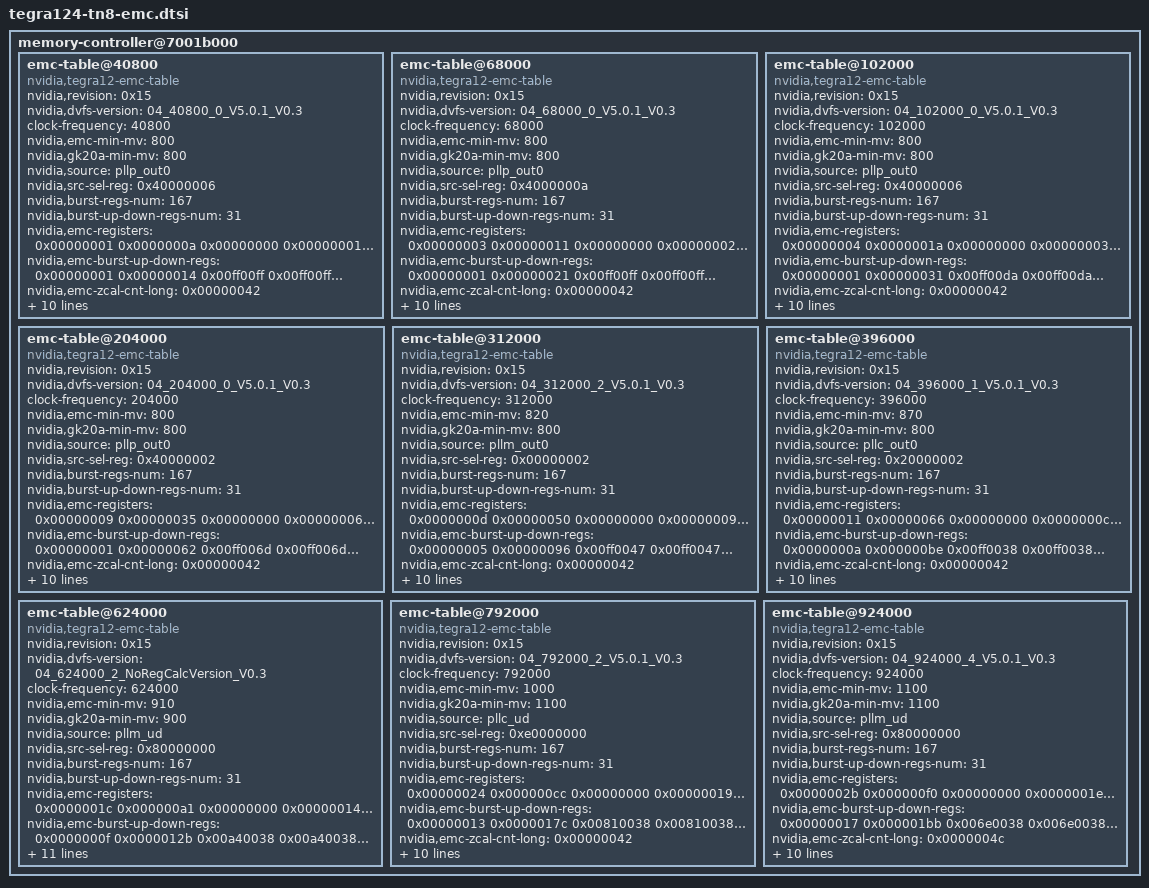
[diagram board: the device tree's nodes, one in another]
memory-controller@7001b000 {
	emc-table@40800 {
		compatible = "nvidia,tegra12-emc-table";
		nvidia,revision = <0x15>;
		nvidia,dvfs-version = "04_40800_0_V5.0.1_V0.3";
		clock-frequency = <40800>;
		nvidia,emc-min-mv = <800>;
		nvidia,gk20a-min-mv = <800>;
		nvidia,source = "pllp_out0";
		nvidia,src-sel-reg = <0x40000006>;
		nvidia,burst-regs-num = <167>;
		nvidia,burst-up-down-regs-num = <31>;
		nvidia,emc-registers = <
			0x00000001
			0x0000000a
			0x00000000
			0x00000001
			0x00000000
			0x00000004
			0x0000000a
			0x00000003
			0x0000000b
			0x00000000
			0x00000000
			0x00000003
			0x00000003
			0x00000000
			0x00000006
			0x00000006
			0x00000006
			0x00000002
			0x00000000
			0x00000005
			0x00000005
			0x00010000
			0x00000004
			0x00000000
			0x00000000
			0x00000000
			0x00000000
			0x00000004
			0x0000000c
			0x0000000d
			0x0000000f
			0x0000012e
			0x00000000
			0x0000004b
			0x00000002
			0x00000002
			0x00000001
			0x00000000
			0x00000008
			0x0000000f
			0x0000000b
			0x0000000b
			0x00000004
			0x00000005
			0x00000004
			0x00000000
			0x00000000
			0x00000005
			0x00000005
			0x00000138
			0x00000000
			0x00000000
			0x00000000
			0x1069aa98
			0x002c00a0
			0x00008000
			0x00064000
			0x00064000
			0x00064000
			0x00064000
			0x00064000
			0x00064000
			0x00064000
			0x00064000
			0x00064000
			0x00064000
			0x00064000
			0x00064000
			0x00064000
			0x00064000
			0x00064000
			0x00064000
			0x00000000
			0x00000000
			0x00000000
			0x00000000
			0x00000000
			0x00000000
			0x00000000
			0x00000000
			0x00000000
			0x00000000
			0x00000000
			0x00000000
			0x00000000
			0x00000000
			0x00000000
			0x00000000
			0x00000000
			0x00000000
			0x00000000
			0x00000000
			0x00000000
			0x00000000
			0x00000000
			0x00000000
			0x00000000
			0x00000000
			0x00000000
			0x00000000
			0x00000000
			0x00000000
			0x00000000
			0x00000000
			0x00000000
			0x00000000
			0x00000000
			0x00000000
			0x00000000
			0x00000000
			0x0007c000
			0x0007c000
			0x0007c000
			0x0007c000
			0x00007c00
			0x00007c00
			0x00007c00
			0x00007c00
			0x100002a0
			0x00000000
			0x00111111
			0x0030a11c
			0x00000000
			0x00000000
			0x77ffc085
			0x00000e0e
			0x81f1f108
			0x07070004
			0x0000003f
			0x016eeeee
			0x51451400
			0x00514514
			0x00514514
			0x51451400
			0x0505003f
			0x00000014
			0x00000000
			0x00000000
			0x00000042
			0x000e000e
			0x000e000e
			0x00000000
			0x00000000
			0xa1430000
			0x00000000
			0x00000004
			0x0000f2f3
			0x80000364
			0x0000000a
			0xb0000001
			0x80000017
			0x00000001
			0x00000001
			0x00000002
			0x00000000
			0x00000002
			0x00000001
			0x00000002
			0x00000008
			0x00000003
			0x00000002
			0x00000003
			0x00000006
			0x06030203
			0x000a0402
			0x74c30303
			0x001f0000>;
		nvidia,emc-burst-up-down-regs = <
			0x00000001
			0x00000014
			0x00ff00ff
			0x00ff00ff
			0x00ff00ff
			0x00ff00ff
			0x00ff00ff
			0x00ff00ff
			0x00ff00ff
			0x00ff0049
			0x00ff0080
			0x00ff0004
			0x00ff0004
			0x000800ff
			0x000000ff
			0x00ff0004
			0x00ff00ff
			0x00ff00ff
			0x00ff0024
			0x00ff00ff
			0x000000ff
			0x000000ff
			0x00ff00ff
			0x000000ff
			0x00ff00ff
			0x00ff00ff
			0x00ff00ff
			0x00ff00ff
			0x00ff00ff
			0x00ff00ff
			0x00ff00ff>;
		nvidia,emc-zcal-cnt-long = <0x00000042>;
		nvidia,emc-acal-interval = <0x001fffff>;
		nvidia,emc-ctt-term_ctrl = <0x00000802>;
		nvidia,emc-cfg = <0x73240000>;
		nvidia,emc-cfg-2 = <0x00000885>;
		nvidia,emc-sel-dpd-ctrl = <0x0004012c>;
		nvidia,emc-cfg-dig-dll = <0x002c0068>;
		nvidia,emc-mode-0 = <0x80001221>;
		nvidia,emc-mode-1 = <0x80100003>;
		nvidia,emc-mode-2 = <0x80200008>;
		nvidia,emc-mode-4 = <0x00000000>;
	};
	emc-table@68000 {
		compatible = "nvidia,tegra12-emc-table";
		nvidia,revision = <0x15>;
		nvidia,dvfs-version = "04_68000_0_V5.0.1_V0.3";
		clock-frequency = <68000>;
		nvidia,emc-min-mv = <800>;
		nvidia,gk20a-min-mv = <800>;
		nvidia,source = "pllp_out0";
		nvidia,src-sel-reg = <0x4000000a>;
		nvidia,burst-regs-num = <167>;
		nvidia,burst-up-down-regs-num = <31>;
		nvidia,emc-registers = <
			0x00000003
			0x00000011
			0x00000000
			0x00000002
			0x00000000
			0x00000004
			0x0000000a
			0x00000003
			0x0000000b
			0x00000000
			0x00000000
			0x00000003
			0x00000003
			0x00000000
			0x00000006
			0x00000006
			0x00000006
			0x00000002
			0x00000000
			0x00000005
			0x00000005
			0x00010000
			0x00000004
			0x00000000
			0x00000000
			0x00000000
			0x00000000
			0x00000004
			0x0000000c
			0x0000000d
			0x0000000f
			0x00000202
			0x00000000
			0x00000080
			0x00000002
			0x00000002
			0x00000001
			0x00000000
			0x0000000f
			0x0000000f
			0x00000013
			0x00000013
			0x00000004
			0x00000005
			0x00000004
			0x00000001
			0x00000000
			0x00000005
			0x00000005
			0x00000213
			0x00000000
			0x00000000
			0x00000000
			0x1069aa98
			0x002c00a0
			0x00008000
			0x00064000
			0x00064000
			0x00064000
			0x00064000
			0x00064000
			0x00064000
			0x00064000
			0x00064000
			0x00064000
			0x00064000
			0x00064000
			0x00064000
			0x00064000
			0x00064000
			0x00064000
			0x00064000
			0x00000000
			0x00000000
			0x00000000
			0x00000000
			0x00000000
			0x00000000
			0x00000000
			0x00000000
			0x00000000
			0x00000000
			0x00000000
			0x00000000
			0x00000000
			0x00000000
			0x00000000
			0x00000000
			0x00000000
			0x00000000
			0x00000000
			0x00000000
			0x00000000
			0x00000000
			0x00000000
			0x00000000
			0x00000000
			0x00000000
			0x00000000
			0x00000000
			0x00000000
			0x00000000
			0x00000000
			0x00000000
			0x00000000
			0x00000000
			0x00000000
			0x00000000
			0x00000000
			0x00000000
			0x0007c000
			0x0007c000
			0x0007c000
			0x0007c000
			0x00007c00
			0x00007c00
			0x00007c00
			0x00007c00
			0x100002a0
			0x00000000
			0x00111111
			0x0030a11c
			0x00000000
			0x00000000
			0x77ffc085
			0x00000e0e
			0x81f1f108
			0x07070004
			0x0000003f
			0x016eeeee
			0x51451400
			0x00514514
			0x00514514
			0x51451400
			0x0505003f
			0x00000022
			0x00000000
			0x00000000
			0x00000042
			0x000e000e
			0x000e000e
			0x00000000
			0x00000000
			0xa1430000
			0x00000000
			0x00000004
			0x0000f2f3
			0x8000050e
			0x0000000a
			0x00000001
			0x8000001e
			0x00000001
			0x00000001
			0x00000002
			0x00000000
			0x00000002
			0x00000001
			0x00000002
			0x00000008
			0x00000003
			0x00000002
			0x00000003
			0x00000006
			0x06030203
			0x000a0402
			0x74230403
			0x001f0000>;
		nvidia,emc-burst-up-down-regs = <
			0x00000001
			0x00000021
			0x00ff00ff
			0x00ff00ff
			0x00ff00b0
			0x00ff00ff
			0x00ff00ec
			0x00ff00ff
			0x00ff00ec
			0x00e90049
			0x00ff0080
			0x00ff0004
			0x00ff0004
			0x000800ff
			0x000000ff
			0x00ff0004
			0x00ff00ff
			0x00ff00a3
			0x00ff0024
			0x00ff00ff
			0x000000ff
			0x000000ef
			0x00ff00ff
			0x000000ef
			0x00ff00ff
			0x00ff00ff
			0x00ee00ef
			0x00ff00ff
			0x00ff00ff
			0x00ff00ff
			0x00ff00ff>;
		nvidia,emc-zcal-cnt-long = <0x00000042>;
		nvidia,emc-acal-interval = <0x001fffff>;
		nvidia,emc-ctt-term_ctrl = <0x00000802>;
		nvidia,emc-cfg = <0x73240000>;
		nvidia,emc-cfg-2 = <0x00000885>;
		nvidia,emc-sel-dpd-ctrl = <0x0004012c>;
		nvidia,emc-cfg-dig-dll = <0x002c0068>;
		nvidia,emc-mode-0 = <0x80001221>;
		nvidia,emc-mode-1 = <0x80100003>;
		nvidia,emc-mode-2 = <0x80200008>;
		nvidia,emc-mode-4 = <0x00000000>;
	};
	emc-table@102000 {
		compatible = "nvidia,tegra12-emc-table";
		nvidia,revision = <0x15>;
		nvidia,dvfs-version = "04_102000_0_V5.0.1_V0.3";
		clock-frequency = <102000>;
		nvidia,emc-min-mv = <800>;
		nvidia,gk20a-min-mv = <800>;
		nvidia,source = "pllp_out0";
		nvidia,src-sel-reg = <0x40000006>;
		nvidia,burst-regs-num = <167>;
		nvidia,burst-up-down-regs-num = <31>;
		nvidia,emc-registers = <
			0x00000004
			0x0000001a
			0x00000000
			0x00000003
			0x00000001
			0x00000004
			0x0000000a
			0x00000003
			0x0000000b
			0x00000001
			0x00000001
			0x00000003
			0x00000003
			0x00000000
			0x00000006
			0x00000006
			0x00000006
			0x00000002
			0x00000000
			0x00000005
			0x00000005
			0x00010000
			0x00000004
			0x00000000
			0x00000000
			0x00000000
			0x00000000
			0x00000004
			0x0000000c
			0x0000000d
			0x0000000f
			0x00000304
			0x00000000
			0x000000c1
			0x00000002
			0x00000002
			0x00000001
			0x00000000
			0x00000018
			0x0000000f
			0x0000001c
			0x0000001c
			0x00000004
			0x00000005
			0x00000004
			0x00000003
			0x00000000
			0x00000005
			0x00000005
			0x0000031c
			0x00000000
			0x00000000
			0x00000000
			0x1069aa98
			0x002c00a0
			0x00008000
			0x00064000
			0x00064000
			0x00064000
			0x00064000
			0x00064000
			0x00064000
			0x00064000
			0x00064000
			0x00064000
			0x00064000
			0x00064000
			0x00064000
			0x00064000
			0x00064000
			0x00064000
			0x00064000
			0x00000000
			0x00000000
			0x00000000
			0x00000000
			0x00000000
			0x00000000
			0x00000000
			0x00000000
			0x00000000
			0x00000000
			0x00000000
			0x00000000
			0x00000000
			0x00000000
			0x00000000
			0x00000000
			0x00000000
			0x00000000
			0x00000000
			0x00000000
			0x00000000
			0x00000000
			0x00000000
			0x00000000
			0x00000000
			0x00000000
			0x00000000
			0x00000000
			0x00000000
			0x00000000
			0x00000000
			0x00000000
			0x00000000
			0x00000000
			0x00000000
			0x00000000
			0x00000000
			0x00000000
			0x0007c000
			0x0007c000
			0x0007c000
			0x0007c000
			0x00007c00
			0x00007c00
			0x00007c00
			0x00007c00
			0x100002a0
			0x00000000
			0x00111111
			0x0030a11c
			0x00000000
			0x00000000
			0x77ffc085
			0x00000e0e
			0x81f1f108
			0x07070004
			0x0000003f
			0x016eeeee
			0x51451400
			0x00514514
			0x00514514
			0x51451400
			0x0505003f
			0x00000033
			0x00000000
			0x00000000
			0x00000042
			0x000e000e
			0x000e000e
			0x00000000
			0x00000000
			0xa1430000
			0x00000000
			0x00000004
			0x0000f2f3
			0x80000713
			0x0000000a
			0x08000001
			0x80000026
			0x00000001
			0x00000001
			0x00000003
			0x00000000
			0x00000002
			0x00000001
			0x00000002
			0x00000008
			0x00000003
			0x00000002
			0x00000003
			0x00000006
			0x06030203
			0x000a0403
			0x73c30504
			0x001f0000>;
		nvidia,emc-burst-up-down-regs = <
			0x00000001
			0x00000031
			0x00ff00da
			0x00ff00da
			0x00ff0075
			0x00ff00ff
			0x00ff009d
			0x00ff00ff
			0x00ff009d
			0x009b0049
			0x00ff0080
			0x00ff0004
			0x00ff0004
			0x000800ad
			0x000000ff
			0x00ff0004
			0x00ff00c6
			0x00ff006d
			0x00ff0024
			0x00ff00d6
			0x000000ff
			0x0000009f
			0x00ff00ff
			0x0000009f
			0x00ff00ff
			0x00ff00ff
			0x009f00a0
			0x00ff00ff
			0x00ff00ff
			0x00ff00ff
			0x00ff00da>;
		nvidia,emc-zcal-cnt-long = <0x00000042>;
		nvidia,emc-acal-interval = <0x001fffff>;
		nvidia,emc-ctt-term_ctrl = <0x00000802>;
		nvidia,emc-cfg = <0x73240000>;
		nvidia,emc-cfg-2 = <0x00000885>;
		nvidia,emc-sel-dpd-ctrl = <0x0004012c>;
		nvidia,emc-cfg-dig-dll = <0x002c0068>;
		nvidia,emc-mode-0 = <0x80001221>;
		nvidia,emc-mode-1 = <0x80100003>;
		nvidia,emc-mode-2 = <0x80200008>;
		nvidia,emc-mode-4 = <0x00000000>;
	};
	emc-table@204000 {
		compatible = "nvidia,tegra12-emc-table";
		nvidia,revision = <0x15>;
		nvidia,dvfs-version = "04_204000_0_V5.0.1_V0.3";
		clock-frequency = <204000>;
		nvidia,emc-min-mv = <800>;
		nvidia,gk20a-min-mv = <800>;
		nvidia,source = "pllp_out0";
		nvidia,src-sel-reg = <0x40000002>;
		nvidia,burst-regs-num = <167>;
		nvidia,burst-up-down-regs-num = <31>;
		nvidia,emc-registers = <
			0x00000009
			0x00000035
			0x00000000
			0x00000006
			0x00000002
			0x00000005
			0x0000000a
			0x00000003
			0x0000000b
			0x00000002
			0x00000002
			0x00000003
			0x00000003
			0x00000000
			0x00000005
			0x00000005
			0x00000006
			0x00000002
			0x00000000
			0x00000004
			0x00000006
			0x00010000
			0x00000004
			0x00000000
			0x00000000
			0x00000000
			0x00000000
			0x00000003
			0x0000000d
			0x0000000f
			0x00000011
			0x00000607
			0x00000000
			0x00000181
			0x00000002
			0x00000002
			0x00000001
			0x00000000
			0x00000032
			0x0000000f
			0x00000038
			0x00000038
			0x00000004
			0x00000005
			0x00000004
			0x00000007
			0x00000000
			0x00000005
			0x00000005
			0x00000638
			0x00000000
			0x00000000
			0x00000000
			0x1069aa98
			0x002c00a0
			0x00008000
			0x00064000
			0x00064000
			0x00064000
			0x00064000
			0x00064000
			0x00064000
			0x00064000
			0x00064000
			0x00064000
			0x00064000
			0x00064000
			0x00064000
			0x00064000
			0x00064000
			0x00064000
			0x00064000
			0x00000000
			0x00000000
			0x00000000
			0x00000000
			0x00000000
			0x00000000
			0x00000000
			0x00000000
			0x00000000
			0x00000000
			0x00008000
			0x00000000
			0x00000000
			0x00008000
			0x00000000
			0x00000000
			0x00000000
			0x00000000
			0x00000000
			0x00000000
			0x00000000
			0x00000000
			0x00000000
			0x00000000
			0x00000000
			0x00000000
			0x00000000
			0x00000000
			0x00000000
			0x00000000
			0x00000000
			0x00000000
			0x00000000
			0x00000000
			0x00000000
			0x00000000
			0x00000000
			0x00000000
			0x0007c000
			0x0007c000
			0x0007c000
			0x0007c000
			0x00007c00
			0x00007c00
			0x00007c00
			0x00007c00
			0x100002a0
			0x00000000
			0x00111111
			0x0030a11c
			0x00000000
			0x00000000
			0x77ffc085
			0x00000707
			0x81f1f108
			0x07070004
			0x0000003f
			0x016eeeee
			0x51451400
			0x00514514
			0x00514514
			0x51451400
			0x0505003f
			0x00000000
			0x00000000
			0x00020000
			0x00000100
			0x000e000e
			0x000e000e
			0x00000000
			0x00000000
			0xa1430000
			0x00000000
			0x00000004
			0x0000d2b3
			0x80000d22
			0x0000000a
			0x01000003
			0x80000040
			0x00000001
			0x00000001
			0x00000004
			0x00000002
			0x00000004
			0x00000001
			0x00000002
			0x00000008
			0x00000003
			0x00000002
			0x00000004
			0x00000006
			0x06040203
			0x000a0404
			0x73840a05
			0x001f0000>;
		nvidia,emc-burst-up-down-regs = <
			0x00000001
			0x00000062
			0x00ff006d
			0x00ff006d
			0x00ff003c
			0x00ff00af
			0x00ff004f
			0x00ff00af
			0x00ff004f
			0x004e0049
			0x00ff0080
			0x00ff0004
			0x00ff0004
			0x00080057
			0x000000ff
			0x00ff0004
			0x00ff0063
			0x00ff0036
			0x00ff0024
			0x00ff006b
			0x000000ff
			0x00000050
			0x00ff00ff
			0x00000050
			0x00ff00ff
			0x00d400ff
			0x00510050
			0x00ff00ff
			0x00ff00ff
			0x00ff00c6
			0x00ff006d>;
		nvidia,emc-zcal-cnt-long = <0x00000042>;
		nvidia,emc-acal-interval = <0x001fffff>;
		nvidia,emc-ctt-term_ctrl = <0x00000802>;
		nvidia,emc-cfg = <0x73200000>;
		nvidia,emc-cfg-2 = <0x0000088d>;
		nvidia,emc-sel-dpd-ctrl = <0x0004012c>;
		nvidia,emc-cfg-dig-dll = <0x002c0068>;
		nvidia,emc-mode-0 = <0x80001221>;
		nvidia,emc-mode-1 = <0x80100003>;
		nvidia,emc-mode-2 = <0x80200008>;
		nvidia,emc-mode-4 = <0x00000000>;
	};
	emc-table@312000 {
		compatible = "nvidia,tegra12-emc-table";
		nvidia,revision = <0x15>;
		nvidia,dvfs-version = "04_312000_2_V5.0.1_V0.3";
		clock-frequency = <312000>;
		nvidia,emc-min-mv = <820>;
		nvidia,gk20a-min-mv = <800>;
		nvidia,source = "pllm_out0";
		nvidia,src-sel-reg = <0x00000002>;
		nvidia,burst-regs-num = <167>;
		nvidia,burst-up-down-regs-num = <31>;
		nvidia,emc-registers = <
			0x0000000d
			0x00000050
			0x00000000
			0x00000009
			0x00000003
			0x00000004
			0x00000008
			0x00000002
			0x00000009
			0x00000003
			0x00000003
			0x00000002
			0x00000002
			0x00000000
			0x00000003
			0x00000003
			0x00000005
			0x00000002
			0x00000000
			0x00000002
			0x00000006
			0x00030000
			0x00000004
			0x00000000
			0x00000000
			0x00000000
			0x00000000
			0x00000002
			0x0000000d
			0x0000000e
			0x00000010
			0x00000942
			0x00000000
			0x00000250
			0x00000001
			0x00000008
			0x00000001
			0x00000000
			0x0000004e
			0x0000000e
			0x00000055
			0x00000200
			0x00000004
			0x00000005
			0x00000004
			0x0000000a
			0x00000000
			0x00000005
			0x00000005
			0x00000982
			0x00000002
			0x00000000
			0x00000000
			0x1049b898
			0x002c00a0
			0x00008000
			0x00030000
			0x00030000
			0x00030000
			0x00030000
			0x00030000
			0x00030000
			0x00030000
			0x00030000
			0x00030000
			0x00030000
			0x00030000
			0x00030000
			0x00030000
			0x00030000
			0x00030000
			0x00030000
			0x00000000
			0x00000000
			0x00000000
			0x00000000
			0x00000000
			0x00000000
			0x00000000
			0x00000000
			0x00040000
			0x00040000
			0x00000000
			0x00040000
			0x00040000
			0x00000000
			0x00000000
			0x00000000
			0x00000000
			0x00000000
			0x00000000
			0x00000000
			0x00000000
			0x00000000
			0x00000000
			0x00000000
			0x00000000
			0x00000000
			0x00000000
			0x00000000
			0x00000000
			0x00000000
			0x00000000
			0x00000000
			0x00000000
			0x00000000
			0x00000000
			0x00000000
			0x00000000
			0x00000000
			0x00040000
			0x00040000
			0x00040000
			0x00040000
			0x00004000
			0x00004000
			0x00004000
			0x00004000
			0x10000280
			0x00000000
			0x00111111
			0x01231339
			0x00000000
			0x00000000
			0x77ffc081
			0x00000505
			0x81f1f108
			0x07070004
			0x00000000
			0x016eeeee
			0x51451420
			0x00514514
			0x00514514
			0x51451400
			0x0000003f
			0x0000009c
			0x00000000
			0x00020000
			0x00000100
			0x0170000e
			0x0170000e
			0x00000000
			0x00000000
			0xa1430000
			0x00000000
			0x00000004
			0x0000d3b3
			0x8000138d
			0x00000009
			0x0b000004
			0x80000040
			0x00000001
			0x00000002
			0x00000007
			0x00000004
			0x00000005
			0x00000001
			0x00000002
			0x00000007
			0x00000002
			0x00000002
			0x00000004
			0x00000006
			0x06040202
			0x000b0607
			0x76e50f08
			0x001f0000>;
		nvidia,emc-burst-up-down-regs = <
			0x00000005
			0x00000096
			0x00ff0047
			0x00ff0047
			0x00ff003c
			0x00ff0090
			0x00ff0041
			0x00ff0090
			0x00ff0041
			0x00330049
			0x00ff0080
			0x00ff0004
			0x00ff0004
			0x00080039
			0x000000ff
			0x00ff0004
			0x00ff0041
			0x00ff002c
			0x00ff0024
			0x00ff0046
			0x000000ff
			0x00000036
			0x00ff00ff
			0x00000036
			0x00ff00ff
			0x00d400ff
			0x00510034
			0x00ff00ff
			0x00ff00ff
			0x00ff0082
			0x00ff0047>;
		nvidia,emc-zcal-cnt-long = <0x00000042>;
		nvidia,emc-acal-interval = <0x001fffff>;
		nvidia,emc-ctt-term_ctrl = <0x00000802>;
		nvidia,emc-cfg = <0x73340000>;
		nvidia,emc-cfg-2 = <0x0000088d>;
		nvidia,emc-sel-dpd-ctrl = <0x0004012c>;
		nvidia,emc-cfg-dig-dll = <0x002c0068>;
		nvidia,emc-mode-0 = <0x80000321>;
		nvidia,emc-mode-1 = <0x80100002>;
		nvidia,emc-mode-2 = <0x80200000>;
		nvidia,emc-mode-4 = <0x00000000>;
	};
	emc-table@396000 {
		compatible = "nvidia,tegra12-emc-table";
		nvidia,revision = <0x15>;
		nvidia,dvfs-version = "04_396000_1_V5.0.1_V0.3";
		clock-frequency = <396000>;
		nvidia,emc-min-mv = <870>;
		nvidia,gk20a-min-mv = <800>;
		nvidia,source = "pllc_out0";
		nvidia,src-sel-reg = <0x20000002>;
		nvidia,burst-regs-num = <167>;
		nvidia,burst-up-down-regs-num = <31>;
		nvidia,emc-registers = <
			0x00000011
			0x00000066
			0x00000000
			0x0000000c
			0x00000004
			0x00000004
			0x00000008
			0x00000002
			0x0000000a
			0x00000004
			0x00000004
			0x00000002
			0x00000002
			0x00000000
			0x00000003
			0x00000003
			0x00000005
			0x00000002
			0x00000000
			0x00000002
			0x00000006
			0x00030000
			0x00000004
			0x00000000
			0x00000000
			0x00000000
			0x00000000
			0x00000002
			0x0000000d
			0x0000000e
			0x00000010
			0x00000bd1
			0x00000000
			0x000002f4
			0x00000001
			0x00000008
			0x00000001
			0x00000000
			0x00000063
			0x0000000f
			0x0000006c
			0x00000200
			0x00000004
			0x00000005
			0x00000004
			0x0000000d
			0x00000000
			0x00000005
			0x00000005
			0x00000c11
			0x00000002
			0x00000000
			0x00000000
			0x1049b898
			0x002c00a0
			0x00008000
			0x00030000
			0x00030000
			0x00030000
			0x00030000
			0x00030000
			0x00030000
			0x00030000
			0x00030000
			0x00030000
			0x00030000
			0x00030000
			0x00030000
			0x00030000
			0x00030000
			0x00030000
			0x00030000
			0x00000000
			0x00000000
			0x00000000
			0x00000000
			0x00000000
			0x00000000
			0x00000000
			0x00000000
			0x00070000
			0x00070000
			0x00000000
			0x00070000
			0x00070000
			0x00000000
			0x00000000
			0x00000000
			0x00000000
			0x00000000
			0x00000000
			0x00000000
			0x00000000
			0x00000000
			0x00000000
			0x00000000
			0x00000000
			0x00000000
			0x00000000
			0x00000000
			0x00000000
			0x00000000
			0x00000000
			0x00000000
			0x00000000
			0x00000000
			0x00000000
			0x00000000
			0x00000000
			0x00000000
			0x00044000
			0x00044000
			0x00044000
			0x00044000
			0x00004400
			0x00004400
			0x00004400
			0x00004400
			0x100002a0
			0x00000000
			0x00111111
			0x0123133d
			0x00000000
			0x00000000
			0x77ffc085
			0x00000505
			0x81f1f108
			0x07070004
			0x00000000
			0x016eeeee
			0x51451420
			0x00514514
			0x00514514
			0x51451400
			0x0000003f
			0x000000c6
			0x00000000
			0x00020000
			0x00000100
			0x015b000e
			0x015b000e
			0x00000000
			0x00000000
			0xa1430000
			0x00000000
			0x00000004
			0x0000d3b3
			0x8000188b
			0x00000009
			0x0f000005
			0x80000040
			0x00000001
			0x00000002
			0x00000009
			0x00000005
			0x00000007
			0x00000001
			0x00000002
			0x00000008
			0x00000002
			0x00000002
			0x00000004
			0x00000006
			0x06040202
			0x000d0709
			0x7586120a
			0x001f0000>;
		nvidia,emc-burst-up-down-regs = <
			0x0000000a
			0x000000be
			0x00ff0038
			0x00ff0038
			0x00ff003c
			0x00ff0090
			0x00ff0041
			0x00ff0090
			0x00ff0041
			0x00280049
			0x00ff0080
			0x00ff0004
			0x00ff0004
			0x0008002d
			0x000000ff
			0x00ff0004
			0x00ff0033
			0x00ff0022
			0x00ff0024
			0x00ff0037
			0x000000ff
			0x00000036
			0x00ff00ff
			0x00000036
			0x00ff00ff
			0x00d400ff
			0x00510029
			0x00ff00ff
			0x00ff00ff
			0x00ff0066
			0x00ff0038>;
		nvidia,emc-zcal-cnt-long = <0x00000042>;
		nvidia,emc-acal-interval = <0x001fffff>;
		nvidia,emc-ctt-term_ctrl = <0x00000802>;
		nvidia,emc-cfg = <0x73340000>;
		nvidia,emc-cfg-2 = <0x0000088d>;
		nvidia,emc-sel-dpd-ctrl = <0x0004012c>;
		nvidia,emc-cfg-dig-dll = <0x002c0068>;
		nvidia,emc-mode-0 = <0x80000521>;
		nvidia,emc-mode-1 = <0x80100002>;
		nvidia,emc-mode-2 = <0x80200000>;
		nvidia,emc-mode-4 = <0x00000000>;
	};
	emc-table@624000 {
		compatible = "nvidia,tegra12-emc-table";
		nvidia,revision = <0x15>;
		nvidia,dvfs-version = "04_624000_2_NoRegCalcVersion_V0.3";
		clock-frequency = <624000>;
		nvidia,emc-min-mv = <910>;
		nvidia,gk20a-min-mv = <900>;
		nvidia,source = "pllm_ud";
		nvidia,src-sel-reg = <0x80000000>;
		nvidia,burst-regs-num = <167>;
		nvidia,burst-up-down-regs-num = <31>;
		nvidia,emc-registers = <
			0x0000001c
			0x000000a1
			0x00000000
			0x00000014
			0x00000007
			0x00000007
			0x0000000b
			0x00000003
			0x00000010
			0x00000007
			0x00000007
			0x00000002
			0x00000002
			0x00000000
			0x00000005
			0x00000005
			0x0000000a
			0x00000002
			0x00000000
			0x00000003
			0x0000000b
			0x00080000
			0x00000004
			0x00000000
			0x00000000
			0x00000000
			0x00000000
			0x00000002
			0x00000012
			0x00000016
			0x00000018
			0x000012c3
			0x00000000
			0x000004b0
			0x00000002
			0x0000000d
			0x00000001
			0x00000000
			0x0000009c
			0x00000015
			0x000000a9
			0x00000200
			0x00000004
			0x00000005
			0x00000004
			0x00000016
			0x00000000
			0x00000007
			0x00000007
			0x00001304
			0x00000002
			0x00000000
			0x00000000
			0x1049b898
			0xe00d01b1
			0x00008000
			0x00000008
			0x00000008
			0x00000008
			0x00000008
			0x00000008
			0x00000008
			0x00000008
			0x00000008
			0x00000008
			0x00000008
			0x00000008
			0x00000008
			0x00000008
			0x00000008
			0x00000008
			0x00000008
			0x00000000
			0x00000000
			0x00000000
			0x00000000
			0x00000000
			0x00000000
			0x00000000
			0x00000000
			0x0000400e
			0x0000400e
			0x00000000
			0x0000400e
			0x0000400e
			0x00000000
			0x00000000
			0x00000000
			0x00000000
			0x00000000
			0x00000000
			0x00000000
			0x00000000
			0x00000000
			0x00000000
			0x00000000
			0x00000000
			0x00000000
			0x00000000
			0x00000000
			0x00000000
			0x00000000
			0x00000000
			0x00000000
			0x00000000
			0x00000000
			0x00000000
			0x00000000
			0x00000000
			0x00000000
			0x0000000a
			0x0000000a
			0x0000000a
			0x0000000a
			0x0000000a
			0x0000000a
			0x0000000a
			0x0000000a
			0x100002a0
			0x00000000
			0x00111111
			0x0020013d
			0x00000000
			0x00000000
			0x77ffc085
			0x00000505
			0x81f1f108
			0x07070004
			0x00000000
			0x016eeeee
			0x51451420
			0x00514514
			0x00514514
			0x51451400
			0x0505003f
			0x00000000
			0x00000000
			0x00020000
			0x00000100
			0x0122000e
			0x0122000e
			0x00000000
			0x00000000
			0xa1430000
			0x00000000
			0x00000004
			0x000040a0
			0x80002617
			0x0000000e
			0x06000009
			0x80000040
			0x00000003
			0x00000004
			0x0000000f
			0x00000009
			0x0000000b
			0x00000001
			0x00000003
			0x0000000b
			0x00000002
			0x00000002
			0x00000005
			0x00000007
			0x07050202
			0x00130b0f
			0x736a1d10
			0x001f0000>;
		nvidia,emc-burst-up-down-regs = <
			0x0000000f
			0x0000012b
			0x00a40038
			0x00a40038
			0x00a4003c
			0x00a40090
			0x00a40041
			0x00a40090
			0x00a40041
			0x00270049
			0x00a40080
			0x00a40004
			0x00a40004
			0x0008001c
			0x000000a4
			0x00a40004
			0x00a40020
			0x00a40018
			0x00a40024
			0x00a40023
			0x000000a4
			0x00000036
			0x00a400a4
			0x00000036
			0x00a400a4
			0x00d400ff
			0x00510029
			0x00a400a4
			0x00a400a4
			0x00a40065
			0x00a40024>;
		nvidia,emc-zcal-cnt-long = <0x00000042>;
		nvidia,emc-acal-interval = <0x001fffff>;
		nvidia,emc-ctt-term_ctrl = <0x00000802>;
		nvidia,emc-cfg = <0x73300000>;
		nvidia,emc-cfg-2 = <0x0000089d>;
		nvidia,emc-sel-dpd-ctrl = <0x00040128>;
		nvidia,emc-cfg-dig-dll = <0xe00d0169>;
		nvidia,emc-mode-0 = <0x80000b61>;
		nvidia,emc-mode-1 = <0x80100002>;
		nvidia,emc-mode-2 = <0x80200010>;
		nvidia,emc-mode-4 = <0x00000000>;
	};
	emc-table@792000 {
		compatible = "nvidia,tegra12-emc-table";
		nvidia,revision = <0x15>;
		nvidia,dvfs-version = "04_792000_2_V5.0.1_V0.3";
		clock-frequency = <792000>;
		nvidia,emc-min-mv = <1000>;
		nvidia,gk20a-min-mv = <1100>;
		nvidia,source = "pllc_ud";
		nvidia,src-sel-reg = <0xe0000000>;
		nvidia,burst-regs-num = <167>;
		nvidia,burst-up-down-regs-num = <31>;
		nvidia,emc-registers = <
			0x00000024
			0x000000cc
			0x00000000
			0x00000019
			0x0000000a
			0x00000007
			0x0000000d
			0x00000004
			0x00000013
			0x0000000a
			0x0000000a
			0x00000003
			0x00000002
			0x00000000
			0x00000006
			0x00000006
			0x0000000b
			0x00000002
			0x00000000
			0x00000003
			0x0000000c
			0x00090000
			0x00000004
			0x00000000
			0x00000000
			0x00000000
			0x00000000
			0x00000002
			0x00000013
			0x00000018
			0x0000001a
			0x000017e2
			0x00000000
			0x000005f8
			0x00000003
			0x00000011
			0x00000001
			0x00000000
			0x000000c6
			0x00000018
			0x000000d6
			0x00000200
			0x00000005
			0x00000006
			0x00000005
			0x0000001d
			0x00000000
			0x00000008
			0x00000008
			0x00001822
			0x00000002
			0x00000000
			0x00000000
			0x1049b898
			0xe00701b1
			0x00008000
			0x00000006
			0x00000006
			0x00000006
			0x00000006
			0x00000006
			0x00000006
			0x00000006
			0x00000006
			0x00000006
			0x00000006
			0x00000006
			0x00000006
			0x00000006
			0x00000006
			0x00000006
			0x00000006
			0x00000000
			0x00000000
			0x00000000
			0x00000000
			0x00000000
			0x00000000
			0x00000000
			0x00000000
			0x0000400e
			0x0000400e
			0x00000000
			0x0000400e
			0x0000400e
			0x00000000
			0x00000000
			0x00000000
			0x00000000
			0x00000000
			0x00000000
			0x00000000
			0x00000000
			0x00000000
			0x00000000
			0x00000000
			0x00000000
			0x00000000
			0x00000000
			0x00000000
			0x00000000
			0x00000000
			0x00000000
			0x00000000
			0x00000000
			0x00000000
			0x00000000
			0x00000000
			0x00000000
			0x00000000
			0x0000000d
			0x0000000d
			0x0000000d
			0x0000000d
			0x0000000d
			0x0000000d
			0x0000000d
			0x0000000d
			0x100002a0
			0x00000000
			0x00111111
			0x0020013d
			0x00000000
			0x00000000
			0x77ffc085
			0x00000505
			0x81f1f108
			0x07070004
			0x00000000
			0x016eeeee
			0x61861820
			0x00514514
			0x00514514
			0x61861800
			0x0505003f
			0x00000000
			0x00000000
			0x00020000
			0x00000100
			0x00f8000e
			0x00f8000e
			0x00000000
			0x00000000
			0xa1430000
			0x00000000
			0x00000004
			0x000040a0
			0x80003012
			0x00000010
			0x0e00000b
			0x80000040
			0x00000004
			0x00000005
			0x00000013
			0x0000000c
			0x0000000f
			0x00000002
			0x00000003
			0x0000000c
			0x00000002
			0x00000002
			0x00000005
			0x00000008
			0x08050202
			0x00170e13
			0x734c2414
			0x001f0000>;
		nvidia,emc-burst-up-down-regs = <
			0x00000013
			0x0000017c
			0x00810038
			0x00810038
			0x0081003c
			0x00810090
			0x00810041
			0x00810090
			0x00810041
			0x00270049
			0x00810080
			0x00810004
			0x00810004
			0x00080016
			0x00000081
			0x00810004
			0x00810019
			0x00810018
			0x00810024
			0x0081001c
			0x00000081
			0x00000036
			0x00810081
			0x00000036
			0x00810081
			0x00d400ff
			0x00510029
			0x00810081
			0x00810081
			0x00810065
			0x0081001c>;
		nvidia,emc-zcal-cnt-long = <0x00000042>;
		nvidia,emc-acal-interval = <0x001fffff>;
		nvidia,emc-ctt-term_ctrl = <0x00000802>;
		nvidia,emc-cfg = <0x73300000>;
		nvidia,emc-cfg-2 = <0x0000089d>;
		nvidia,emc-sel-dpd-ctrl = <0x00040000>;
		nvidia,emc-cfg-dig-dll = <0xe0070169>;
		nvidia,emc-mode-0 = <0x80000d71>;
		nvidia,emc-mode-1 = <0x80100002>;
		nvidia,emc-mode-2 = <0x80200018>;
		nvidia,emc-mode-4 = <0x00000000>;
	};
	emc-table@924000 {
		compatible = "nvidia,tegra12-emc-table";
		nvidia,revision = <0x15>;
		nvidia,dvfs-version = "04_924000_4_V5.0.1_V0.3";
		clock-frequency = <924000>;
		nvidia,emc-min-mv = <1100>;
		nvidia,gk20a-min-mv = <1100>;
		nvidia,source = "pllm_ud";
		nvidia,src-sel-reg = <0x80000000>;
		nvidia,burst-regs-num = <167>;
		nvidia,burst-up-down-regs-num = <31>;
		nvidia,emc-registers = <
			0x0000002b
			0x000000f0
			0x00000000
			0x0000001e
			0x0000000b
			0x00000008
			0x0000000f
			0x00000005
			0x00000016
			0x0000000b
			0x0000000b
			0x00000004
			0x00000002
			0x00000000
			0x00000007
			0x00000007
			0x0000000e
			0x00000002
			0x00000000
			0x00000003
			0x0000000e
			0x000b0000
			0x00000004
			0x00000000
			0x00000000
			0x00000000
			0x00000000
			0x00000002
			0x00000015
			0x0000001a
			0x0000001c
			0x00001be7
			0x00000000
			0x000006f9
			0x00000004
			0x00000015
			0x00000001
			0x00000000
			0x000000e7
			0x0000001b
			0x00000132
			0x00000200
			0x00000006
			0x00000007
			0x00000006
			0x00000022
			0x00000000
			0x0000000a
			0x0000000a
			0x00001c28
			0x00000000
			0x00000000
			0x00000000
			0x1049b898
			0xe00401b1
			0x00008000
			0x00000003
			0x00000003
			0x00000003
			0x00000003
			0x00000003
			0x00000003
			0x00000003
			0x00000003
			0x00000003
			0x00000003
			0x00000003
			0x00000003
			0x00000003
			0x00000003
			0x00000003
			0x00000003
			0x00000000
			0x00000000
			0x00000000
			0x00000000
			0x00000000
			0x00000000
			0x00000000
			0x00000000
			0x00040000
			0x00040000
			0x00000000
			0x00040000
			0x00040000
			0x00000000
			0x00000000
			0x00000000
			0x00000000
			0x00000000
			0x00000000
			0x00000000
			0x00000000
			0x00000000
			0x00000000
			0x00000000
			0x00000000
			0x00000000
			0x00000000
			0x00000000
			0x00000000
			0x00000000
			0x00000000
			0x00000000
			0x00000000
			0x00000000
			0x00000000
			0x00000000
			0x00000000
			0x00000000
			0x0000000a
			0x0000000a
			0x0000000a
			0x0000000a
			0x0000000a
			0x0000000a
			0x0000000a
			0x0000000a
			0x100002a0
			0x00000000
			0x00111111
			0x0120113d
			0x00000000
			0x00000000
			0x77ffc085
			0x00000505
			0x81f1f108
			0x07070004
			0x00000000
			0x016eeeee
			0x5d75d720
			0x00514514
			0x00514514
			0x5d75d700
			0x0606003f
			0x00000000
			0x00000000
			0x00020000
			0x00000128
			0x00cd000e
			0x00cd000e
			0x00000000
			0x00000000
			0xa1430000
			0x00000000
			0x00000004
			0x00004080
			0x800037ea
			0x00000011
			0x0e00000d
			0x80000040
			0x00000005
			0x00000006
			0x00000016
			0x0000000e
			0x00000011
			0x00000002
			0x00000004
			0x0000000e
			0x00000002
			0x00000002
			0x00000006
			0x00000009
			0x09060202
			0x001a1016
			0x738e2a17
			0x001f0000>;
		nvidia,emc-burst-up-down-regs = <
			0x00000017
			0x000001bb
			0x006e0038
			0x006e0038
			0x006e003c
			0x006e0090
			0x006e0041
			0x006e0090
			0x006e0041
			0x00270049
			0x006e0080
			0x006e0004
			0x006e0004
			0x00080016
			0x0000006e
			0x006e0004
			0x006e0019
			0x006e0018
			0x006e0024
			0x006e001b
			0x0000006e
			0x00000036
			0x006e006e
			0x00000036
			0x006e006e
			0x00d400ff
			0x00510029
			0x006e006e
			0x006e006e
			0x006e0065
			0x006e001c>;
		nvidia,emc-zcal-cnt-long = <0x0000004c>;
		nvidia,emc-acal-interval = <0x001fffff>;
		nvidia,emc-ctt-term_ctrl = <0x00000802>;
		nvidia,emc-cfg = <0x73300000>;
		nvidia,emc-cfg-2 = <0x0000089d>;
		nvidia,emc-sel-dpd-ctrl = <0x00040000>;
		nvidia,emc-cfg-dig-dll = <0xe0040169>;
		nvidia,emc-mode-0 = <0x80000f15>;
		nvidia,emc-mode-1 = <0x80100002>;
		nvidia,emc-mode-2 = <0x80200020>;
		nvidia,emc-mode-4 = <0x00000000>;
	};
};

